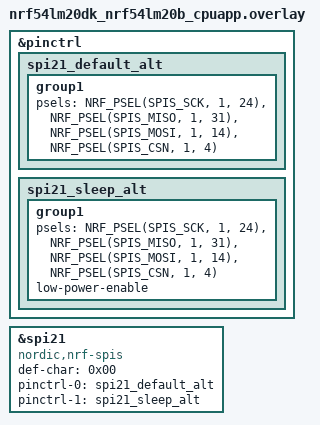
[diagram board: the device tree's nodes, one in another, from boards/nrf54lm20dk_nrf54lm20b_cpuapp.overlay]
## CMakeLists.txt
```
cmake_minimum_required(VERSION 3.20.0)
find_package(Zephyr REQUIRED HINTS $ENV{ZEPHYR_BASE})
project(spi_slave)

target_sources(app PRIVATE src/main.c)
```

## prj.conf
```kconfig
CONFIG_SPI=y
CONFIG_SPI_SLAVE=y
CONFIG_SPI_ASYNC=y
CONFIG_POLL=y
CONFIG_PRINTK=y
CONFIG_GPIO=y
CONFIG_PM=n
```

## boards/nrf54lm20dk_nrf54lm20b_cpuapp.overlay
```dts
/* SPI slave using spi21 — same pins as Nordic's working test */

&pinctrl {
	spi21_default_alt: spi21_default_alt {
		group1 {
			psels = <NRF_PSEL(SPIS_SCK, 1, 24)>,
				<NRF_PSEL(SPIS_MISO, 1, 31)>,
				<NRF_PSEL(SPIS_MOSI, 1, 14)>,
				<NRF_PSEL(SPIS_CSN, 1, 4)>;
		};
	};

	spi21_sleep_alt: spi21_sleep_alt {
		group1 {
			psels = <NRF_PSEL(SPIS_SCK, 1, 24)>,
				<NRF_PSEL(SPIS_MISO, 1, 31)>,
				<NRF_PSEL(SPIS_MOSI, 1, 14)>,
				<NRF_PSEL(SPIS_CSN, 1, 4)>;
			low-power-enable;
		};
	};
};

dut_spis: &spi21 {
	compatible = "nordic,nrf-spis";
	status = "okay";
	def-char = <0x00>;
	pinctrl-0 = <&spi21_default_alt>;
	pinctrl-1 = <&spi21_sleep_alt>;
	pinctrl-names = "default", "sleep";
	/delete-property/ rx-delay-supported;
	/delete-property/ rx-delay;
};
```

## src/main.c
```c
/*
 * SPI Slave — receives a byte from master and responds.
 * Uses spi21 with Nordic's proven pin assignments.
 *
 * Note: SPIS spi_transceive returns rx_amount (bytes received) on success,
 * NOT 0. So ret > 0 means success, ret < 0 means error.
 */

#include <zephyr/kernel.h>
#include <zephyr/device.h>
#include <zephyr/drivers/spi.h>

#define SPI_NODE DT_NODELABEL(spi21)

static const struct device *spi_dev = DEVICE_DT_GET(SPI_NODE);

static struct spi_config spi_cfg = {
	.frequency = 1000000,
	.operation = SPI_WORD_SET(8) | SPI_TRANSFER_MSB | SPI_OP_MODE_SLAVE,
	.slave = 0,
};

int main(void)
{
	printk("=== SPI Slave ===\n");

	if (!device_is_ready(spi_dev)) {
		printk("SPI device not ready!\n");
		return 0;
	}
	printk("SPI device ready, waiting for master...\n");

	uint8_t rx_byte = 0;
	uint8_t tx_byte = 0x55;

	while (1) {
		struct spi_buf tx_buf = { .buf = &tx_byte, .len = 1 };
		struct spi_buf_set tx_set = { .buffers = &tx_buf, .count = 1 };

		struct spi_buf rx_buf = { .buf = &rx_byte, .len = 1 };
		struct spi_buf_set rx_set = { .buffers = &rx_buf, .count = 1 };

		int ret = spi_transceive(spi_dev, &spi_cfg, &tx_set, &rx_set);
		if (ret < 0) {
			printk("SPI error: %d\n", ret);
		} else {
			printk("Received: 0x%02X (ret=%d)\n", rx_byte, ret);
			tx_byte = rx_byte + 1;
		}
	}

	return 0;
}
```
